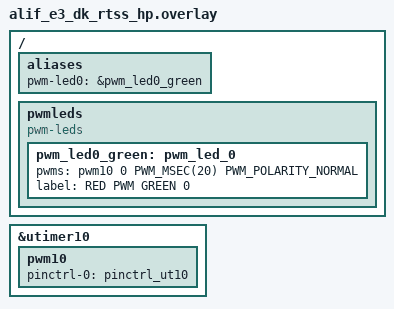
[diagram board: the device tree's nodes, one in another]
/* Copyright (c) 2025 Alif Semiconductor
 *
 * SPDX-License-Identifier: Apache-2.0
 */

/ {
	aliases {
		pwm-led0 = &pwm_led0_green;
	};

	pwmleds {
		compatible = "pwm-leds";
		pwm_led0_green: pwm_led_0 {
			pwms = <&pwm10 0 PWM_MSEC(20) PWM_POLARITY_NORMAL>;
			label = "RED PWM GREEN 0";
		};
	};

};

&utimer10 {
	status = "okay";

	pwm10: pwm10 {
		pinctrl-0 = <&pinctrl_ut10>;
		pinctrl-names = "default";
		status = "okay";
	};
};
